# CY8C5888AXI_LP096 register map
File version: 0.1
CY8C58LP
Registers are 8-bit, read-write, no defined reset value unless marked. A register's access mark holds for its fields unless they carry their own. Offsets are from the block's base; lines under a group give offsets from that group; [hi:lo] are bit positions; {n}, {i} and the like mark numbered series; 'fields as' and 'values as' point back to an identical list; <NAME> marks a mode.

## Memory map
0x00000000 Digital_Out_Control
0x00000000 Digital_Input_Status
0x00000000 PRS
0x00000000 Wave_Control
0x00000000 Digital_PWM
0x00000000 Trig_Buf
0x00000000 Trigger_Control
0x00000000 Trigger_Comp
0x00000000 Vtrigger
0x00000000 USBUART — USBFS
0x00000000 ADC_2 — SAR ADC
0x00000000 ADC_1 — SAR ADC
0x00000000 Wave_DAC_VDAC8
0x00000000 Wave_Buf
0x00000000 PWM_Sample_Buffer
0x00000000 Trigger_Status

## Digital_Out_Control
Base 0x00000000
0x40006473 Digital_Out_Control_CONTROL_REG

## Digital_Input_Status
Base 0x00000000
0x40006462 Digital_Input_Status_STATUS_REG
0x40006482 Digital_Input_Status_MASK_REG
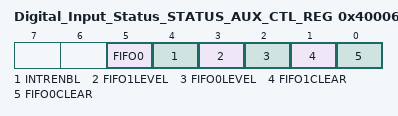
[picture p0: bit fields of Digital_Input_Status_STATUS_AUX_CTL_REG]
0x40006492 Digital_Input_Status_STATUS_AUX_CTL_REG
  [5] FIFO0 — FIFO0 clear
    1=ENABLED (Enable counter); 0=DISABLED (Disable counter)
  [4] INTRENBL — Enables or disables the Interrupt
    1=ENABLED (Interrupt enabled); 0=DISABLED (Interrupt disabled)
  [3] FIFO1LEVEL — FIFO level
    1=ENABLED (FIFO LVL: input mode: FIFO at least 1/2 empty; output mode: FIFO at least 1/2 full); 0=DISABLED (FIFO LVL: input mode: FIFO not full; output mode: FIFO not empty)
  [2] FIFO0LEVEL — FIFO level
    values as FIFO1LEVEL
  [1] FIFO1CLEAR — FIFO clear
    1=ENABLED (Clear FIFO state); 0=DISABLED (Normal FIFO operation)
  [0] FIFO0CLEAR — FIFO clear
    values as FIFO1CLEAR

## PRS
Base 0x00000000
0x40006504 SINGLE_CYCLE_SEED 16-bit — Current seed value
0x40006524 SINGLE_CYCLE_POLYNOMIAL 16-bit — Current polynomial value
0x40006544 SINGLE_CYCLE_COPY 16-bit — Copy seed value

## Wave_Control
Base 0x00000000
0x40006475 Wave_Control_CONTROL_REG

## Digital_PWM
Base 0x00000000
0x40006420 Digital_PWM__COMPARE1 — UDB.D0 - Assigned Compare1 Value
0x40006430 Digital_PWM__COMPARE2 — UDB.D1 - Assigned Compare2 Value
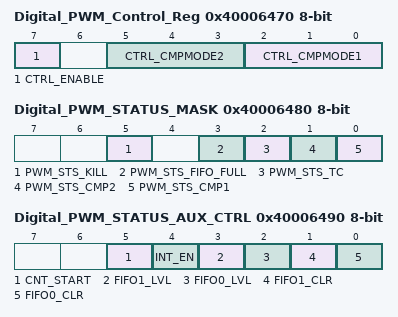
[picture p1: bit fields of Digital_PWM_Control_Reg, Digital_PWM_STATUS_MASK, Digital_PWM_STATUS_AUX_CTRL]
0x40006470 Digital_PWM_Control_Reg — UDB Control Register - Assigned Control Register Value
  [7] CTRL_ENABLE — Enable the PWM
  [5:3] CTRL_CMPMODE2 — Compare mode 2
  [2:0] CTRL_CMPMODE1 — Compare mode 1
0x40006480 Digital_PWM_STATUS_MASK — UDB Status bits Interrupt Mask Enable Register
  [5] PWM_STS_KILL ro — Enables the Interrupt on Kill
  [3] PWM_STS_FIFO_FULL ro — FIFO Full Status Mask
  [2] PWM_STS_TC ro — Enables the Interrupt on Terminal Count
  [1] PWM_STS_CMP2 ro — Enables the Interrupt on Compare 2
  [0] PWM_STS_CMP1 ro — Enables the Interrupt on Compare 1
0x40006490 Digital_PWM_STATUS_AUX_CTRL — UDB Auxilliary Control Register
  [5] CNT_START — FIFO0 clear
    0=E_CNT_START0 (Disable counter); 1=E_CNT_START1 (Enable counter)
  [4] INT_EN
    0=E_INT_EN0 (Interrupt disabled); 1=E_INT_EN1 (Interrupt enabled)
  [3] FIFO1_LVL — FIFO level
    0=E_FIFO_LVL_0 (FIFO LVL: input mode: FIFO not full; output mode: FIFO not empty); 1=E_FIFO_LVL_1 (FIFO LVL: input mode: FIFO at least 1/2 empty; output mode: FIFO at least 1/2 full)
  [2] FIFO0_LVL — FIFO level
    values as FIFO1_LVL
  [1] FIFO1_CLR — FIFO1 clear
    0=E_FIFO_CLR_0 (Normal FIFO operation); 1=E_FIFO_CLR_1 (Clear FIFO state)
  [0] FIFO0_CLR — FIFO0 clear
    values as FIFO1_CLR

## Trig_Buf
Base 0x00000000
0x400043A4 PM_ACT_CFG4 — Active Power Mode Configuration Register 4
  [3:0] EN_OPAMP — Enables subsystems during active power mode
    0=Blk_0 (Enables analog linear output buffer for Opamp block 0); 2=Blk_1 (Enables analog linear output buffer for Opamp block 1); 4=Blk_2 (Enables analog linear output buffer for Opamp block 2); 8=Blk_3 (Enables analog linear output buffer for Opamp block 3)
0x400043B4 PM_STBY_CFG4 — Standby Power Mode Configuration Register 4
  [3:0] EN_OPAMP — Enables subsystems during standby power mode
    values as PM_ACT_CFG4.EN_OPAMP
0x40004624 OPAMP__TR0 — Analog Output Buffer Trim Register 0
  [4:0] offset_trim — Offset Trim: 420uV typical step size; +/- 6.8mV offset trimmable range
0x40004625 OPAMP__TR1 — Analog Output Buffer Trim Register 1
0x4000585C OPAMP__CR — Analog Output Buffer Configuration Register
  [1:0] pwr_mode — Power Mode
    0=Default_Fast (Default Power mode Fast); 1=Slow (Power Mode Slow); 2=Medium (Power Mode Medium); 3=Fast (Power Mode Fast)
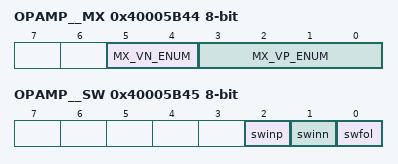
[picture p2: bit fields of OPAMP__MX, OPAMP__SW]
0x40005B44 OPAMP__MX — Analog Buffer Input Selection Register
  [5:4] MX_VN_ENUM — MUX select VN (Negative terminal input)
    0=OPAMP0_MX_VN_DEFAULT (Default - Not Connected (NC)); 1=OPAMP0_MX_VN_AG4 (MUX Selection AGL(4)); 2=OPAMP0_MX_VN_AG6 (MUX Selection AGL(6)); 3=OPAMP0_MX_VN_0x3 (Reserved (NC))
  [3:0] MX_VP_ENUM — MUX select VP (Positive terminal input)
    0=OPAMP0_MX_VP_DEFAULT (Default - Not Connected (NC)); {v}=OPAMP0_MX_VP_AG{v+3} (MUX Selection AGL({v+3})) (v=1..4); {v}=OPAMP0_MX_VP_ABUS{v-5} (MUX Selection ABUSL({v-5})) (v=5..8); 9=OPAMP0_MX_VP_VREF (MUX Selection: OPAMP Voltage Reference); {v}=OPAMP0_MX_VP_H_{0x0+v} (Reserved (NC)) (v=10..15)
0x40005B45 OPAMP__SW — Analog Buffer Routing Switch Register
  [2] swinp — Switch Enable Positive Input
  [1] swinn — Switch Enable Negative Input
  [0] swfol — Switch Enable Follow
